# K510 register map
Vendor: Canaan; File version: 1.0
Canaan K510 unofficial SVD file maintained by community
Registers are 32-bit, read-write, reset 0x0 unless marked. A register's access mark holds for its fields unless they carry their own. Offsets are from the block's base; lines under a group give offsets from that group; [hi:lo] are bit positions; {n}, {i} and the like mark numbered series; 'fields as' and 'values as' point back to an identical list; <NAME> marks a mode.

## Memory map
{0x96000000+0x10000*n} UART{n} (n=0..3) size 0x1000 — Universal Asynchronous Receivers/Transmitters
0x97000000 SYSCTL size 0x10000 — System Control
{0x97010000+0x10000*n} WDT{n} (n=0..2) size 0x10000 — Watch Dog Timer
0x97050000 GPIO size 0x1000 — General Purpose I/O
0x9E000000 MTIMER — Machine Timer
0x9E400000 PLIC_SW — software Platform-Level Interrupt Controller
0x9EC00000 PLIC — Platform-Level Interrupt Controller

## Interrupts
1 UART0 (UART{n})
2 UART1 (UART{n})
3 UART2 (UART{n})
4 UART3 (UART{n})
19 GPIO
20 SYSCTL

## WDT{n} — Watch Dog Timer
Base 0x97010000; array of 3, step 0x10000
0x00 WDT_CR — control register
0x04 WDT_TORR — timeout rage
0x08 WDT_CCVR — current counter
0x0C WDT_CRR — counter restart
0x10 WDT_STAT — interrupt status
0x14 WDT_EOI — interrupt clear
0x1C WDT_PROT_LEVEL — protection level
0xE4 WDT_COMP_PARAM_{x} (x=5,4,3,2,1; step 0x4) — parameters info
0xF8 WDT_COMP_VERSION — version info
0xFC WDT_COMP_TYPE — type info

## MTIMER — Machine Timer
Base 0x9E000000
0x00 MTIME 64-bit (reset mask 0xFFFFFFFF) — real-time counter register . A constant frequency real-time counter. A timer interrupt is generated when mtime >= mtimecmp
{0x8+8i} MTIMECMP{i} (i=0..1) 64-bit reset 0xFFFFFFFFFFFFFFFF (reset mask 0xFFFFFFFF) — stores a 64-bit value for comparing with mtime for generate core[i] timer interrupt stores a 64-bit value for comparing with mtime for generate core[i] timer interrupt when mtime >= mtimecmp[i]

## PLIC_SW — software Platform-Level Interrupt Controller
Base 0x9E400000
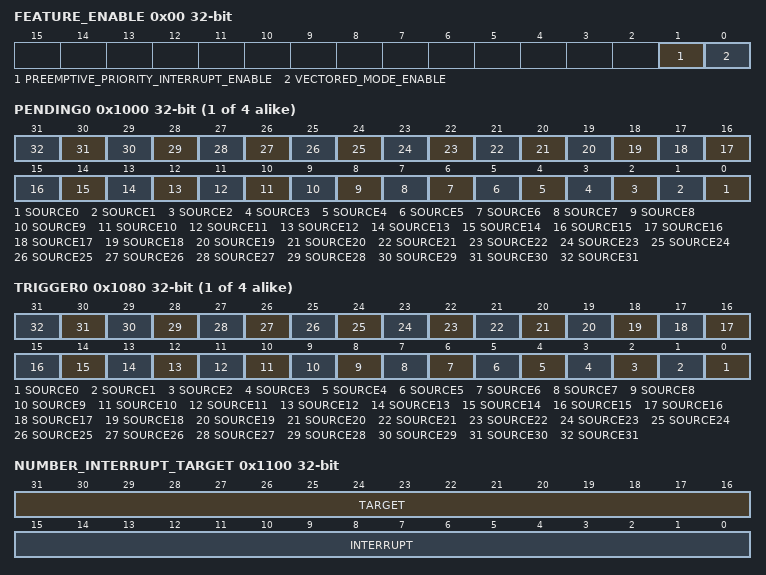
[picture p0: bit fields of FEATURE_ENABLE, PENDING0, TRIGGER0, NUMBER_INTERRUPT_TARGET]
0x00 FEATURE_ENABLE
  [1] PREEMPTIVE_PRIORITY_INTERRUPT_ENABLE
    0=DISABLED (Preemptive priority interrupt feature is Disabled); 1=ENABLED (Preemptive priority interrupt feature is Enabled)
  [0] VECTORED_MODE_ENABLE — Enable Vectored Mode for PLIC . AX25MP not support vector mode
    0=DISABLED (Vectored mode is Disabled); 1=ENABLED (Vectored mode is Enabled)
{0x0+4i} SOURCE{i}_PRIORITY (i=1..127) reset 0x1 (reset mask 0xF) — Priority Register for Source[i]
  [7:0] PRIORITY — Interrupt Source Priority
{0x1000+4i} PENDING{i} (i=0..3) — Souce[i:i+31] interrupt pending
  [n] SOURCE{n} (n=0..31) — Source[i] interrupt pending status
    0=NOT_PENDING (Source[i] interrupt is not pending); 1=PENDING (Source[i] interrupt is pending)
{0x1080+4i} TRIGGER{i} (i=0..3) — Souce[i:i+31] interrupt trigger type
  [n] SOURCE{n} (n=0..31) — Source[i] interrupt trigger type
    0=LEVEL (Level Triggered); 1=EDGE (Edge Triggered)
0x1100 NUMBER_INTERRUPT_TARGET ro — Number of interrupt and target configuration register
  [31:16] TARGET — Number of supported target
  [15:0] INTERRUPT — Number of supported interrupt
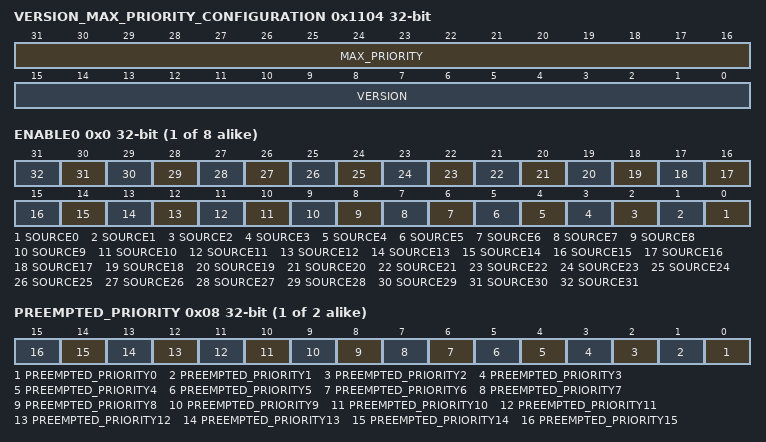
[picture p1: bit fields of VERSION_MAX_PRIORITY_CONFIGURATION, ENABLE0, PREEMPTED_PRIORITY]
0x1104 VERSION_MAX_PRIORITY_CONFIGURATION ro — Version and Maximum priority configuration register
  [31:16] MAX_PRIORITY — The maximum priority supported
  [15:0] VERSION — The version of the AndeStar V5 PLIC design
{0x2000+0x80*i} TARGET{i}_ENABLE (i=0..1) group — Target[M] enable registers
  {0x0+4j} ENABLE{j} (j=0..3) — Target[i:i+31] enable registers
    [n] SOURCE{n} (n=0..31) — SOURCE[i] enable status
      0=DISABLED (Target[i] is disabled); 1=ENABLED (Target[i] is enabled)
{0x200000+0x1000*i} CONTEXT{i} (i=0..1) group — Target[M]'s context: priority threshold, claim and complete, preempted priority
  0x00 THRESHOLD — Target[M]'s priority threshold register
    [15:0] THRESHOLD — Target[M]'s priority threshold
  0x04 CLAIM_COMPLETE — Target[M]'s claim and complete register
    [15:0] CLAIM_COMPLETE range 0..127 — Target[M]'s claim and complete
  0x08 PREEMPTED_PRIORITY — Target[M]'s preempted priority register provide the preempted priority stack information for each target
    [n] PREEMPTED_PRIORITY{n} (n=0..15) — Target[M]'s preempted priority[P]
      0=NO_PREEMPTED (This priority no preempted by a higher priority interrupt); 1=PREEMPTED (This priority has been preempted by a higher priority interrupt)
